# PIC32CK1012GC01100 device description
Architecture: CORTEX-M33; Family: PIC32CK; Series: PIC32CKGC01
Registers are 32-bit, read-write, reset 0x0 unless marked. A register's access mark holds for its fields unless they carry their own. Offsets are from the block's base; [hi:lo] are bit positions; {n}, {i} and the like mark numbered series; 'fields as' and 'values as' point back to an identical list.

## MCRAMC — Multi-Channel RAM Controller
Instances: FLEXRAM 0x44028000
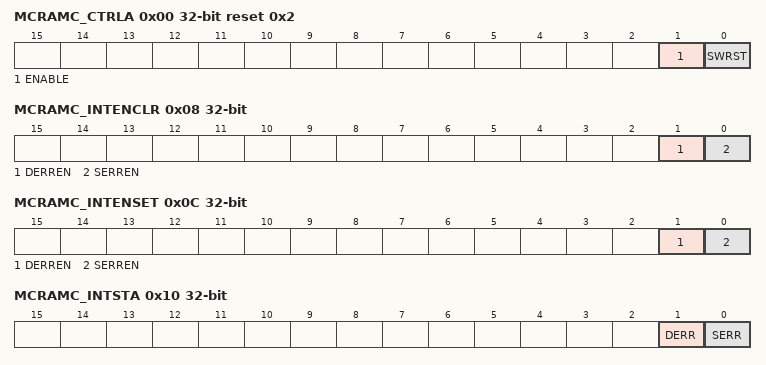
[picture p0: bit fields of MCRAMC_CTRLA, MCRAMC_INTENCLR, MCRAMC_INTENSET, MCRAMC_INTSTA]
0x00 MCRAMC_CTRLA reset 0x2 — Control Enable A Register
  [1] ENABLE — ECC Decoder Enable
    0=ECC decoding is disabled; 1=ECC decoding is enabled
  [0] SWRST — Software Reset
    0=No effect; 1=Reset the MCRAMC. A software-triggered hardware reset of the MCRAMC user interface is performed.
0x08 MCRAMC_INTENCLR (atomic clear) — Interrupt Enable Clear Register
  [1] DERREN — Double Bit Error Interrupt Enable, Clear
  [0] SERREN — Single Bit Error Interrupt Enable, Clear
0x0C MCRAMC_INTENSET (atomic set) — Interrupt Enable Set Register
  [1] DERREN — Double Bit Error Interrupt Enable, Set
  [0] SERREN — Single Bit Error Interrupt Enable, Set
0x10 MCRAMC_INTSTA (atomic clear) — Interrupt Status Register
  [1] DERR — Double Bit Error
  [0] SERR — Single Bit Error
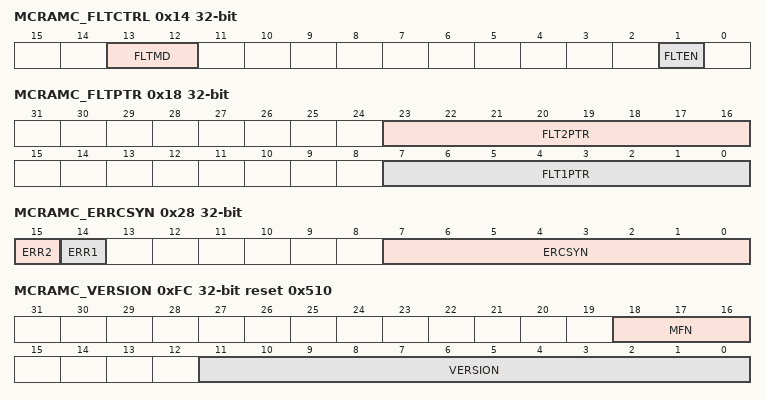
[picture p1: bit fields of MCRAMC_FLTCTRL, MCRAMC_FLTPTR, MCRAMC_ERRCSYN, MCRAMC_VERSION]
0x14 MCRAMC_FLTCTRL — Fault Injection Control Register
  [13:12] FLTMD — Fault Injection Mode
  [1] FLTEN — Fault Injection Enabled
    0=Disables fault injection; 1=Enables fault injection at FLTADR address offset as selected by FLTMD and FLTxPTR
0x18 MCRAMC_FLTPTR — Fault Injection Pointer Register
  [23:16] FLT2PTR — Double Fault Injection Bit Pointer
  [7:0] FLT1PTR — Single Fault Injection Bit Pointer
0x1C MCRAMC_FLTADR — Fault Injection Address Register
  [23:0] FLTADR — Fault Address Offset
0x20 MCRAMC_ERRCADR ro — Error Capture Address Register
  [23:0] ERCADR — ECC SECDED Error Capture Address
0x24 MCRAMC_ERRCPAR ro — Error Capture Parity Register
  [7:0] ERCPAR — ECC SECDED Error Capture Parity
0x28 MCRAMC_ERRCSYN ro — Error Capture Syndrome Register
  [15] ERR2 — ECC Double Bit Error
    0=Not a Double bit error; 1=Double bit error
  [14] ERR1 — ECC Single Bit Error
  [7:0] ERCSYN — ECC SECDED Error Capture Syndrome
    0=Not a Single bit error; 1=Single bit error
0xFC MCRAMC_VERSION ro reset 0x510 — Version Register
  [18:16] MFN — Metal Fix Number
  [11:0] VERSION — MCRAMC Version

## MPU — Memory Protection Unit
Instances: MPU 0xE000ED90
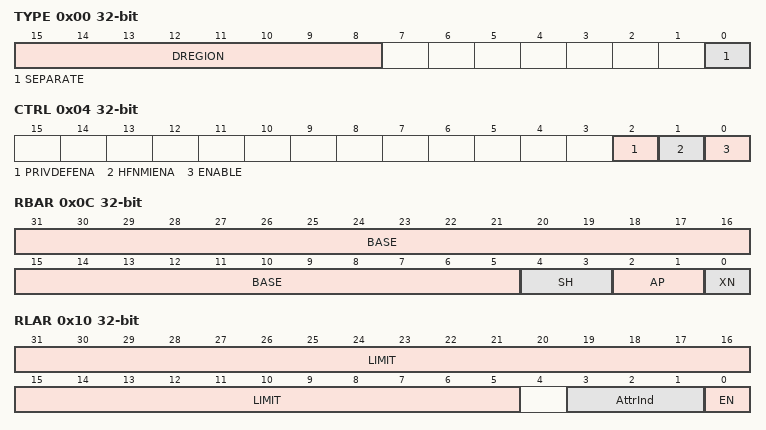
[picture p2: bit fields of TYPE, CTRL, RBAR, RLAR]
0x00 TYPE ro reset not defined — MPU Type Register
  [15:8] DREGION — Number of MPU data regions
  [0] SEPARATE — Separate instructions and data address regions
0x04 CTRL reset not defined — MPU Control Register
  [2] PRIVDEFENA — Privileged default enable
  [1] HFNMIENA — HardFault, NMI enable
  [0] ENABLE — MPU enable
0x08 RNR reset not defined — MPU Region Number Register
  [7:0] REGION — Selected region number
0x0C RBAR reset not defined — MPU Region Base Address Register
  [31:5] BASE — Base address
  [4:3] SH — Shareability
    0=NO (Non-shareable); 2=OUTER (Outer shareable); 3=INNER (Inner shareable)
  [2:1] AP — Access permissions
    0=RWPRIV (Read/write by privileged code only); 1=RWANY (Read/write by any privilege level); 2=RPRIV (Read-only by privileged code only); 3=RANY (Read-only by any privilege level)
  [0] XN — Execute Never
0x10 RLAR reset not defined — MPU Region Limit Address Register
  [31:5] LIMIT — Limit address
  [3:1] AttrInd — Attribute Index
  [0] EN — Region enable
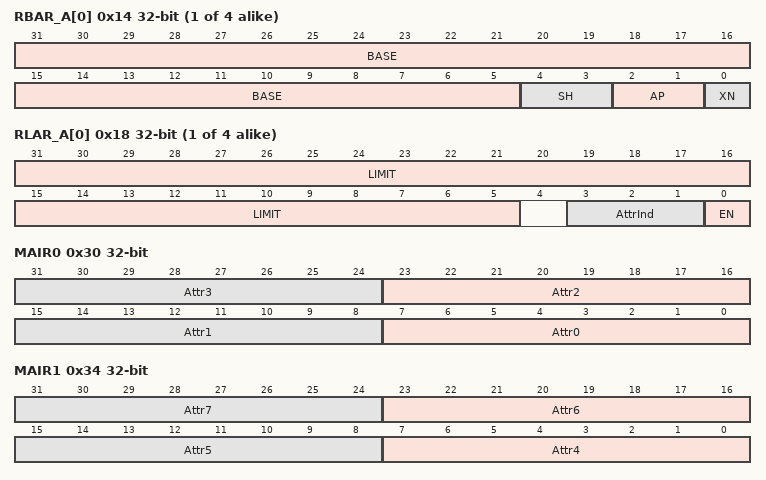
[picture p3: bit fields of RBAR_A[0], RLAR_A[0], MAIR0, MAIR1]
{0x14+4i} RBAR_A[{i}] (i=0..3) reset not defined — MPU Region Base Address Register Alias x
  fields as RBAR
{0x18+4i} RLAR_A[{i}] (i=0..3) reset not defined — MPU Region Limit Address Register Alias x
  fields as RLAR
0x30 MAIR0 reset not defined — MPU Memory Attribute Indirection Register 0
  [8n+7:8n] Attr{n} (n=0..3) — Attribute of MPU region {n}
0x34 MAIR1 reset not defined — MPU Memory Attribute Indirection Register 1
  [8n-25:8n-32] Attr{n} (n=4..7) — Attribute of MPU region {n}

## NVIC — Nested Vectored Interrupt Controller
Instances: NVIC 0xE000E100
{0x0+4i} ISER[{i}] (i=0..4) reset not defined — Interrupt Set Enable Register n
  [31:0] SETENA — Set enable
{0x80+4i} ICER[{i}] (i=0..4) reset not defined — Interrupt Clear Enable Register n
  [31:0] CLRENA — Clear enable
{0x100+4i} ISPR[{i}] (i=0..4) reset not defined — Interrupt Set Pending Register n
  [31:0] SETPEND — Set pending
{0x180+4i} ICPR[{i}] (i=0..4) reset not defined — Interrupt Clear Pending Register n
  [31:0] CLRPEND — Clear pending
{0x200+4i} IABR[{i}] (i=0..4) ro reset not defined — Interrupt Active Bit Register n
  [31:0] ACTIVE — Active state
{0x280+4i} ITNS[{i}] (i=0..4) reset not defined — Interrupt Target Non-secure Register n
  [31:0] ITNS — Interrupt Targets Non-secure
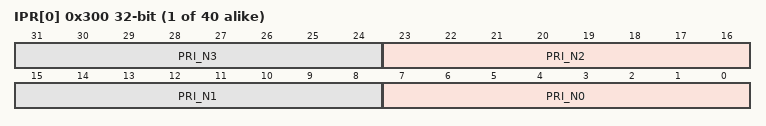
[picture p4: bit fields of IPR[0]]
{0x300+4i} IPR[{i}] (i=0..39) reset not defined — Interrupt Priority Register n
  [8n+7:8n] PRI_N{n} (n=0..3) — Priority of interrupt number 4n+{n}
0xE00 STIR wo reset not defined — Software Triggered Interrupt Register
  [8:0] INTID — Interrupt ID of the interrupt to trigger, in the range 0-479. For example, a value of 0x03 specifies interrupt IRQ3.

## Notices in the file
Copyright (c) 2021 Microchip Technology Inc.
SPDX-License-Identifier: Apache-2.0
Licensed under the Apache License, Version 2.0 (the "License");
you may not use this file except in compliance with the License.
You may obtain a copy of the License at
http://www.apache.org/licenses/LICENSE-2.0
Unless required by applicable law or agreed to in writing, software
distributed under the License is distributed on an "AS IS" BASIS,
WITHOUT WARRANTIES OR CONDITIONS OF ANY KIND, either express or implied.
See the License for the specific language governing permissions and
limitations under the License.
